# NSS_0_CFG_QMGR0_CFG register map
Vendor: Texas Instruments
Peripheral module from a debugger description file (folder 66AK2G0x_66AK2G1x).
Registers are 32-bit, access not given, reset 0x0 unless marked. A register's access mark holds for its fields unless they carry their own. Offsets are as the file gives them; lines under a group give offsets from that group; [hi:lo] are bit positions; {n}, {i} and the like mark numbered series; 'fields as' and 'values as' point back to an identical list; <NAME> marks a mode.

## NSS_0_CFG_QMGR0_CFG
0x00 QM_REVISION_REG ro reset 0x8EFC1900
  [31:0] REV — TI internal data. Identifies revision of peripheral.
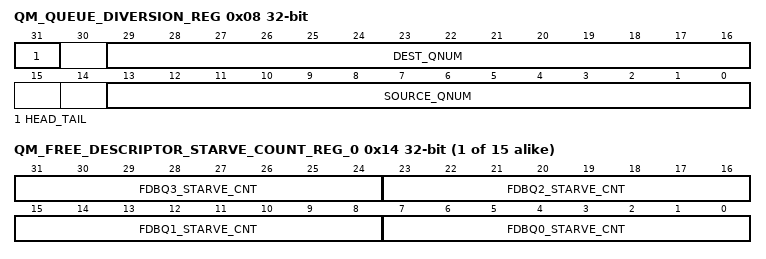
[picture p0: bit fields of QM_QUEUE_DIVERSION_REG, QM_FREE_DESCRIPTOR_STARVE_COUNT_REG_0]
0x08 QM_QUEUE_DIVERSION_REG access per field
  [31] HEAD_TAIL wo — Indicates whether queue contents should be merged on to head or tail of destination queue. Clear this field for head and set for tail.
  [29:16] DEST_QNUM wo — Destination queue number
  [13:0] SOURCE_QNUM wo — Source queue number
0x0C QM_LINKING_RAM_REGION_0_BASE_ADDRESS_REG rw
  [31:2] REGION0_BASE — This field stores the base address for the first region of the linking RAM. This may be anywhere in 32-bit address space but would be typically located in on-chip memory.
0x10 QM_LINKING_RAM_REGION_0_SIZE_REG access per field
  [18:0] REGION0_SIZE rw — This field indicates the number of entries that are contained in the linking RAM region 0. A descriptor with index less than REGION0_SIZE value has its linking location in region 0. A descriptor with index greater than REGION0_SIZE has its linking location in region 1. The queue manager will add the index (left shifted by 3 bits) to the appropriate REGIONX_BASE_ADDR to get the absolute 32-bit address to the linking location for a descriptor.
{0x14+4i} QM_FREE_DESCRIPTOR_STARVE_COUNT_REG_{i} (i=0..14)
  [31:24] FDBQ3_STARVE_CNT — This field increments each time the Free Descriptor/Buffer Queue \[(N*4) + 3\]==3 is read while it is empty. This field is cleared when read. (access COR)
  [23:16] FDBQ2_STARVE_CNT — This field increments each time the Free Descriptor/Buffer Queue \[(N*4) + 2\]==2 is read while it is empty. This field is cleared when read. (access COR)
  [15:8] FDBQ1_STARVE_CNT — This field increments each time the Free Descriptor/Buffer Queue \[(N*4) +1\]==1 is read while it is empty. This field is cleared when read. (access COR)
  [7:0] FDBQ0_STARVE_CNT — This field increments each time the Free Descriptor/Buffer Queue \[(N*4) \]==0 is read while it is empty. This field is cleared when read. (access COR)
0x14 QM_LINKING_RAM_REGION_1_BASE_ADDRESS_REG rw
  [31:2] REGION1_BASE — This field stores the base address for the first region of the linking RAM. This may be anywhere in 32-bit address space but would be typically located in on-chip memory.
